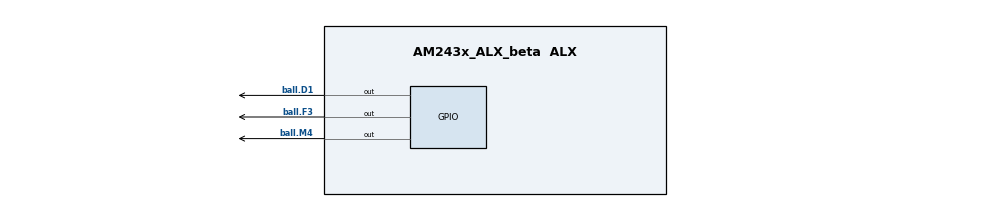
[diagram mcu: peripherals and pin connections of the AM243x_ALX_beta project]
/**
 * @cliArgs --device "AM243x_ALX_beta" --package "ALX" --part "ALX" --context "r5fss0-0" --product "MCU_PLUS_SDK_AM243x@08.06.00"
 * @versions {"tool":"1.14.0+2667"}
 */

/**
 * Import the modules used in this configuration.
 */
const eeprom     = scripting.addModule("/board/eeprom/eeprom", {}, false);
const eeprom1    = eeprom.addInstance();
const led        = scripting.addModule("/board/led/led", {}, false);
const led1       = led.addInstance();
const gpio       = scripting.addModule("/drivers/gpio/gpio", {}, false);
const gpio1      = gpio.addInstance();
const gpio2      = gpio.addInstance();
const gpio3      = gpio.addInstance();
const i2c        = scripting.addModule("/drivers/i2c/i2c", {}, false);
const i2c1       = i2c.addInstance();
const pruicss    = scripting.addModule("/drivers/pruicss/pruicss", {}, false);
const pruicss1   = pruicss.addInstance();
const debug_log  = scripting.addModule("/kernel/dpl/debug_log");
const mpu_armv7  = scripting.addModule("/kernel/dpl/mpu_armv7", {}, false);
const mpu_armv71 = mpu_armv7.addInstance();
const mpu_armv72 = mpu_armv7.addInstance();
const mpu_armv73 = mpu_armv7.addInstance();
const mpu_armv74 = mpu_armv7.addInstance();
const mpu_armv75 = mpu_armv7.addInstance();
const enet_icss  = scripting.addModule("/networking/enet_icss/enet_icss", {}, false);
const enet_icss1 = enet_icss.addInstance();
const enet_icss2 = enet_icss.addInstance();

/**
 * Write custom configuration values to the imported modules.
 */
eeprom1.$name = "CONFIG_EEPROM0";

led1.$name = "CONFIG_LED0";
led1.name  = "TPIC2810";

gpio1.$name                = "CONFIG_GPIO1_35";
gpio1.GPIO.$assign         = "GPIO1";
gpio1.GPIO.gpioPin.pu_pd   = "pu";
gpio1.GPIO.gpioPin.$assign = "ball.M4";

gpio2.$name                = "CONFIG_GPIO1_38";
gpio2.GPIO.$assign         = "GPIO1";
gpio2.GPIO.gpioPin.pu_pd   = "pd";
gpio2.GPIO.gpioPin.$assign = "ball.D1";

gpio3.$name                = "CONFIG_GPIO1_39";
gpio3.GPIO.$assign         = "GPIO1";
gpio3.GPIO.gpioPin.pu_pd   = "pd";
gpio3.GPIO.gpioPin.$assign = "ball.F3";

led1.peripheralDriver    = i2c1;
i2c1.$name               = "CONFIG_I2C0";
eeprom1.peripheralDriver = i2c1;
i2c1.I2C.$assign         = "I2C0";

debug_log.enableUartLog        = true;
debug_log.uartLog.$name        = "CONFIG_UART_CONSOLE";
debug_log.uartLog.UART.$assign = "USART0";

mpu_armv71.$name             = "CONFIG_MPU_REGION0";
mpu_armv71.size              = 31;
mpu_armv71.attributes        = "Device";
mpu_armv71.accessPermissions = "Supervisor RD+WR, User RD";
mpu_armv71.allowExecute      = false;

mpu_armv72.$name             = "CONFIG_MPU_REGION1";
mpu_armv72.size              = 15;
mpu_armv72.accessPermissions = "Supervisor RD+WR, User RD";

mpu_armv73.$name             = "CONFIG_MPU_REGION2";
mpu_armv73.baseAddr          = 0x41010000;
mpu_armv73.size              = 15;
mpu_armv73.accessPermissions = "Supervisor RD+WR, User RD";

mpu_armv74.$name             = "CONFIG_MPU_REGION3";
mpu_armv74.accessPermissions = "Supervisor RD+WR, User RD";
mpu_armv74.baseAddr          = 0x70000000;
mpu_armv74.size              = 21;

mpu_armv75.$name             = "CONFIG_MPU_REGION4";
mpu_armv75.baseAddr          = 0x60000000;
mpu_armv75.size              = 28;
mpu_armv75.accessPermissions = "Supervisor RD, User RD";

enet_icss1.$name                          = "CONFIG_ENET_ICSS0";
enet_icss1.mode                           = "DUAL MAC";
enet_icss1.phyToMacInterfaceMode          = "RGMII";
enet_icss1.QoS                            = 3;
enet_icss1.mdioMode                       = "MDIO_MODE_MANUAL";
enet_icss1.LargePoolPktCount              = 16;
enet_icss1.PktPoolEnable                  = false;
enet_icss1.txDmaChannel[0].$name          = "ENET_DMA_TX_CH0";
enet_icss1.txDmaChannel[0].PacketsCount   = 8;
enet_icss1.rxDmaChannel[0].$name          = "ENET_DMA_RX_CH0";
enet_icss1.rxDmaChannel[0].PacketsCount   = 8;
enet_icss1.rxDmaChannel[0].useDefaultFlow = true;

enet_icss2.$name                          = "CONFIG_ENET_ICSS1";
enet_icss2.mode                           = "DUAL MAC";
enet_icss2.phyToMacInterfaceMode          = "RGMII";
enet_icss2.dualMacPortSelected            = "ENET_MAC_PORT_2";
enet_icss2.QoS                            = 3;
enet_icss2.LargePoolPktCount              = 16;
enet_icss2.mdioMdcEnable                  = false;
enet_icss2.txDmaChannel[0].$name          = "ENET_DMA_TX_CH1";
enet_icss2.txDmaChannel[0].PacketsCount   = 8;
enet_icss2.rxDmaChannel[0].$name          = "ENET_DMA_RX_CH1";
enet_icss2.rxDmaChannel[0].PacketsCount   = 8;
enet_icss2.rxDmaChannel[0].useDefaultFlow = true;

pruicss1.$name                                                                    = "CONFIG_PRU_ICSS0";
enet_icss1.icss                                                                   = pruicss1;
enet_icss2.icss                                                                   = pruicss1;
pruicss1.iepSyncMode                                                              = true;
pruicss1.AdditionalICSSSettings[0].$name                                          = "CONFIG_PRU_ICSS_IO0";
pruicss1.AdditionalICSSSettings[0].PruIepIO.create(1);
pruicss1.AdditionalICSSSettings[0].PruIepIO[0].$name                              = "CONFIG_PRU_ICSS_IEP_IO0";
pruicss1.AdditionalICSSSettings[0].PruIepIO[0].PRU_ICSSG0_IEP.EDC_SYNC_OUT0.$used = true;
pruicss1.intcMapping.create(11);
pruicss1.intcMapping[0].$name                                                     = "CONFIG_ICSS1_INTC_MAPPING0";
pruicss1.intcMapping[1].$name                                                     = "CONFIG_ICSS1_INTC_MAPPING1";
pruicss1.intcMapping[1].event                                                     = "41";
pruicss1.intcMapping[1].channel                                                   = "1";
pruicss1.intcMapping[2].$name                                                     = "CONFIG_ICSS1_INTC_MAPPING2";
pruicss1.intcMapping[2].event                                                     = "53";
pruicss1.intcMapping[2].channel                                                   = "0";
pruicss1.intcMapping[3].$name                                                     = "CONFIG_ICSS1_INTC_MAPPING3";
pruicss1.intcMapping[3].event                                                     = "40";
pruicss1.intcMapping[3].channel                                                   = "1";
pruicss1.intcMapping[4].$name                                                     = "CONFIG_ICSS1_INTC_MAPPING4";
pruicss1.intcMapping[4].event                                                     = "39";
pruicss1.intcMapping[4].channel                                                   = "1";
pruicss1.intcMapping[5].$name                                                     = "CONFIG_ICSS1_INTC_MAPPING5";
pruicss1.intcMapping[5].event                                                     = "52";
pruicss1.intcMapping[5].channel                                                   = "0";
pruicss1.intcMapping[6].$name                                                     = "CONFIG_ICSS1_INTC_MAPPING6";
pruicss1.intcMapping[6].event                                                     = "51";
pruicss1.intcMapping[6].channel                                                   = "0";
pruicss1.intcMapping[7].$name                                                     = "CONFIG_ICSS1_INTC_MAPPING7";
pruicss1.intcMapping[7].event                                                     = "26";
pruicss1.intcMapping[7].channel                                                   = "3";
pruicss1.intcMapping[7].host                                                      = "1";
pruicss1.intcMapping[8].$name                                                     = "CONFIG_ICSS1_INTC_MAPPING8";
pruicss1.intcMapping[8].event                                                     = "27";
pruicss1.intcMapping[8].channel                                                   = "4";
pruicss1.intcMapping[8].host                                                      = "0";
pruicss1.intcMapping[9].$name                                                     = "CONFIG_ICSS1_INTC_MAPPING9";
pruicss1.intcMapping[9].event                                                     = "35";
pruicss1.intcMapping[9].channel                                                   = "7";
pruicss1.intcMapping[10].$name                                                    = "CONFIG_ICSS1_INTC_MAPPING10";
pruicss1.intcMapping[10].channel                                                  = "8";
pruicss1.intcMapping[10].event                                                    = "42";

const udma         = scripting.addModule("/drivers/udma/udma", {}, false);
const udma1        = udma.addInstance({}, false);
enet_icss1.udmaDrv = udma1;
enet_icss2.udmaDrv = udma1;

/**
 * Pinmux solution for unlocked pins/peripherals. This ensures that minor changes to the automatic solver in a future
 * version of the tool will not impact the pinmux you originally saw.  These lines can be completely deleted in order to
 * re-solve from scratch.
 */
i2c1.I2C.SCL.$suggestSolution                                                                = "ball.B16";
i2c1.I2C.SDA.$suggestSolution                                                                = "ball.B15";
debug_log.uartLog.UART.RXD.$suggestSolution                                                  = "ball.B10";
debug_log.uartLog.UART.TXD.$suggestSolution                                                  = "ball.B11";
enet_icss1.PRU_ICSSG1_MDIO.$suggestSolution                                                  = "PRU_ICSSG1_MDIO0";
enet_icss1.PRU_ICSSG1_MDIO.MDC.$suggestSolution                                              = "ball.W1";
enet_icss1.PRU_ICSSG1_MDIO.MDIO.$suggestSolution                                             = "ball.V2";
enet_icss1.PRU_ICSSG1_IEP.$suggestSolution                                                   = "PRU_ICSSG1_IEP0";
enet_icss1.PRU_ICSSG1_IEP.EDC_LATCH_IN0.$suggestSolution                                     = "ball.Y4";
enet_icss1.PRU_ICSSG1_IEP.EDC_SYNC_OUT0.$suggestSolution                                     = "ball.U3";
enet_icss1.PRU_ICSSG1_RGMII1.$suggestSolution                                                = "PRU_ICSSG1_RGMII2";
enet_icss1.PRU_ICSSG1_RGMII1.RD0.$suggestSolution                                            = "ball.AA10";
enet_icss1.PRU_ICSSG1_RGMII1.RD1.$suggestSolution                                            = "ball.Y10";
enet_icss1.PRU_ICSSG1_RGMII1.RD2.$suggestSolution                                            = "ball.Y11";
enet_icss1.PRU_ICSSG1_RGMII1.RD3.$suggestSolution                                            = "ball.V12";
enet_icss1.PRU_ICSSG1_RGMII1.RXC.$suggestSolution                                            = "ball.V10";
enet_icss1.PRU_ICSSG1_RGMII1.RX_CTL.$suggestSolution                                         = "ball.Y12";
enet_icss1.PRU_ICSSG1_RGMII1.TD0.$suggestSolution                                            = "ball.Y6";
enet_icss1.PRU_ICSSG1_RGMII1.TD1.$suggestSolution                                            = "ball.AA8";
enet_icss1.PRU_ICSSG1_RGMII1.TD2.$suggestSolution                                            = "ball.Y9";
enet_icss1.PRU_ICSSG1_RGMII1.TD3.$suggestSolution                                            = "ball.W9";
enet_icss1.PRU_ICSSG1_RGMII1.TXC.$suggestSolution                                            = "ball.Y8";
enet_icss1.PRU_ICSSG1_RGMII1.TX_CTL.$suggestSolution                                         = "ball.V9";
enet_icss2.PRU_ICSSG1_RGMII2.$suggestSolution                                                = "PRU_ICSSG1_RGMII1";
enet_icss2.PRU_ICSSG1_RGMII2.RD0.$suggestSolution                                            = "ball.V4";
enet_icss2.PRU_ICSSG1_RGMII2.RD1.$suggestSolution                                            = "ball.W5";
enet_icss2.PRU_ICSSG1_RGMII2.RD2.$suggestSolution                                            = "ball.AA4";
enet_icss2.PRU_ICSSG1_RGMII2.RD3.$suggestSolution                                            = "ball.Y5";
enet_icss2.PRU_ICSSG1_RGMII2.RXC.$suggestSolution                                            = "ball.Y2";
enet_icss2.PRU_ICSSG1_RGMII2.RX_CTL.$suggestSolution                                         = "ball.AA5";
enet_icss2.PRU_ICSSG1_RGMII2.TD0.$suggestSolution                                            = "ball.V5";
enet_icss2.PRU_ICSSG1_RGMII2.TD1.$suggestSolution                                            = "ball.W2";
enet_icss2.PRU_ICSSG1_RGMII2.TD2.$suggestSolution                                            = "ball.V6";
enet_icss2.PRU_ICSSG1_RGMII2.TD3.$suggestSolution                                            = "ball.AA7";
enet_icss2.PRU_ICSSG1_RGMII2.TXC.$suggestSolution                                            = "ball.W6";
enet_icss2.PRU_ICSSG1_RGMII2.TX_CTL.$suggestSolution                                         = "ball.Y7";
pruicss1.AdditionalICSSSettings[0].PruIepIO[0].PRU_ICSSG0_IEP.$suggestSolution               = "PRU_ICSSG0_IEP0";
pruicss1.AdditionalICSSSettings[0].PruIepIO[0].PRU_ICSSG0_IEP.EDC_SYNC_OUT0.$suggestSolution = "ball.G2";
